VERSION ""

NS_ :

BS_:

BU_:

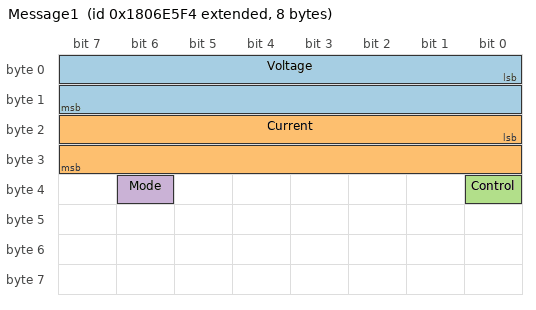
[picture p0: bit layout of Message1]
BO_ 2550588916 Message1: 8 Vector__XXX
	SG_ Voltage : 0|16@1+ (0.1,0) [0|4400] "V" Vector__XXX
	SG_ Current : 16|16@1+ (0.1,0) [0|100] "A" Vector__XXX
	SG_ Control : 32|1@1+ (1,0) [0|0] "" Vector__XXX
	SG_ Mode : 38|1@1+ (1,0) [0|0] "" Vector__XXX

BO_ 2566869221 Message2: 8 Vector__XXX
	SG_ Voltage : 0|16@1+ (0.1,0) [0|4400] "V" Vector__XXX
	SG_ Current : 16|32@1+ (0.1,0) [0|100] "A" Vector__XXX

CM_ BO_ 2550588916 "BMS to Charger";
CM_ SG_ 2550588916 Voltage "Charge voltage";
CM_ BO_ 2566869221 "Charger to BMS";
CM_ SG_ 2566869221 Voltage "Charge voltage";
BA_DEF_ SG_  "SPN" INT 0 524287;
BA_DEF_ BO_  "VFrameFormat" ENUM  "StandardCAN","ExtendedCAN","reserved","J1939PG";
BA_DEF_  "DatabaseVersion" STRING ;
BA_DEF_  "BusType" STRING ;
BA_DEF_  "ProtocolType" STRING ;
BA_DEF_  "DatabaseCompiler" STRING ;
BA_DEF_DEF_  "SPN" 0;
BA_DEF_DEF_  "VFrameFormat" "J1939PG";
BA_DEF_DEF_  "DatabaseVersion" "DEMO PLUS";
BA_DEF_DEF_  "BusType" "";
BA_DEF_DEF_  "ProtocolType" "";
BA_DEF_DEF_  "DatabaseCompiler" "";
BA_ "ProtocolType" "J1939";
BA_ "BusType" "CAN";
BA_ "DatabaseCompiler" "CSS ELECTRONICS (WWW.CSSELECTRONICS.COM)";
BA_ "DatabaseVersion" "1.0.0";
BA_ "SPN" SG_ 2364540158 EngineSpeed 190;
BA_ "SPN" SG_ 2566844926 WheelBasedVehicleSpeed 84;
